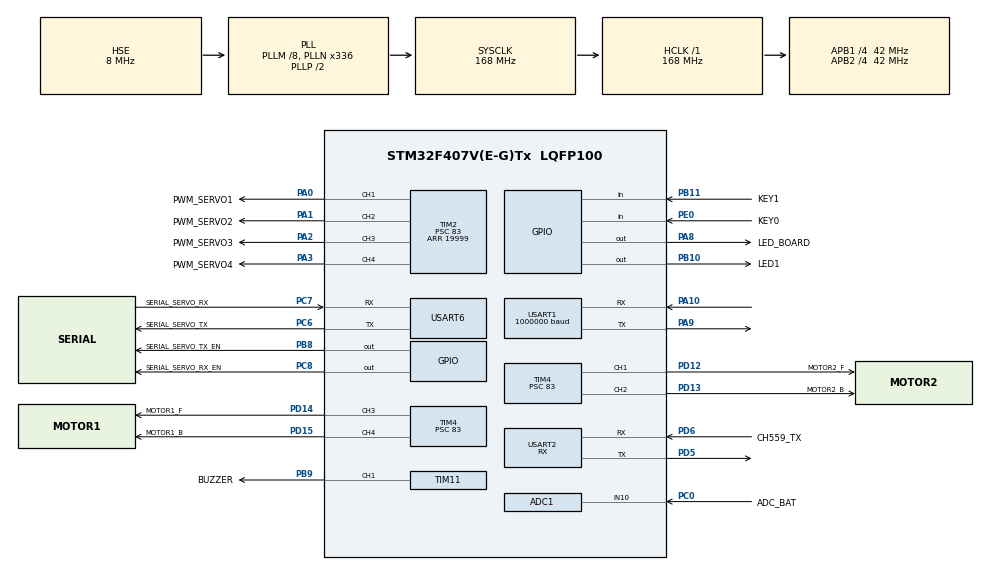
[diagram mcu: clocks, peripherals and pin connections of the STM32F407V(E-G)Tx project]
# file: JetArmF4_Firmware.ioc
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ADC1.Channel-0\#ChannelRegularConversion=ADC_CHANNEL_10
ADC1.NbrOfConversionFlag=1
ADC1.Rank-0\#ChannelRegularConversion=1
ADC1.SamplingTime-0\#ChannelRegularConversion=ADC_SAMPLETIME_3CYCLES
ADC1.master=1
Dma.Request0=USART1_RX
Dma.Request1=USART1_TX
Dma.USART1_RX.0.Direction=DMA_PERIPH_TO_MEMORY
Dma.USART1_RX.0.FIFOMode=DMA_FIFOMODE_DISABLE
Dma.USART1_RX.0.Instance=DMA2_Stream2
Dma.USART1_RX.0.MemDataAlignment=DMA_MDATAALIGN_BYTE
Dma.USART1_RX.0.MemInc=DMA_MINC_ENABLE
Dma.USART1_RX.0.Mode=DMA_NORMAL
Dma.USART1_RX.0.PeriphDataAlignment=DMA_PDATAALIGN_BYTE
Dma.USART1_RX.0.PeriphInc=DMA_PINC_DISABLE
Dma.USART1_RX.0.Priority=DMA_PRIORITY_HIGH
Dma.USART1_TX.1.Direction=DMA_MEMORY_TO_PERIPH
Dma.USART1_TX.1.FIFOMode=DMA_FIFOMODE_DISABLE
Dma.USART1_TX.1.Instance=DMA2_Stream7
Dma.USART1_TX.1.MemDataAlignment=DMA_MDATAALIGN_BYTE
Dma.USART1_TX.1.MemInc=DMA_MINC_ENABLE
Dma.USART1_TX.1.Mode=DMA_NORMAL
Dma.USART1_TX.1.PeriphDataAlignment=DMA_PDATAALIGN_BYTE
Dma.USART1_TX.1.PeriphInc=DMA_PINC_DISABLE
Dma.USART1_TX.1.Priority=DMA_PRIORITY_HIGH
FREERTOS.BinarySemaphores01=serial_servo_rx_complete,Dynamic,NULL;packet_tx_idle,Dynamic,NULL;packet_rx_not_empty,Dynamic,NULL
FREERTOS.Queues01=led0_ctrl_queue,5,16,1,Dynamic,NULL,NULL;led1_ctrl_queue,5,16,1,Dynamic,NULL,NULL;packet_tx_queue,32,void*,0,Dynamic,NULL,NULL
FREERTOS.Tasks01=defaultTask,24,256,StartDefaultTask,Default,NULL,Dynamic,NULL,NULL;app_main_task,25,512,app_main,As weak,NULL,Dynamic,NULL,NULL;packet_rx_task,37,2048,packet_rx_task_entry,As weak,NULL,Dynamic,NULL,NULL;packet_tx_task,35,1024,packet_tx_task_entry,As weak,NULL,Dynamic,NULL,NULL
FREERTOS.Timers01=buzzer_timer,buzzer_timer_callback,osTimerPeriodic,As weak,NULL,Dynamic,NULL;led_timer,led_timer_callback,osTimerPeriodic,As weak,NULL,Dynamic,NULL;button_timer,button_timer_callback,osTimerPeriodic,As weak,NULL,Dynamic,NULL
FREERTOS.configENABLE_FPU=1
FREERTOS.configMINIMAL_STACK_SIZE=256
FREERTOS.configTOTAL_HEAP_SIZE=25360
FREERTOS.configUSE_MALLOC_FAILED_HOOK=1
Mcu.Family=STM32F4
Mcu.Name=STM32F407V(E-G)Tx
Mcu.Package=LQFP100
NVIC.DMA2_Stream2_IRQn=true\:5\:0\:true\:true\:true\:3\:true\:false\:true\:true
NVIC.DMA2_Stream7_IRQn=true\:5\:0\:true\:true\:true\:4\:true\:false\:true\:true
NVIC.PriorityGroup=NVIC_PRIORITYGROUP_4
NVIC.TIM2_IRQn=true\:6\:0\:true\:true\:true\:1\:true\:true\:false\:true
NVIC.TIM8_TRG_COM_TIM14_IRQn=true\:15\:0\:true\:false\:true\:false\:false\:true\:true
NVIC.TimeBase=TIM8_TRG_COM_TIM14_IRQn
NVIC.TimeBaseIP=TIM14
NVIC.USART1_IRQn=true\:7\:0\:true\:true\:true\:2\:true\:true\:true\:true
NVIC.USART6_IRQn=true\:5\:0\:true\:true\:true\:5\:true\:true\:false\:true
PA0-WKUP.GPIO_Label=PWM_SERVO1
PA0-WKUP.Signal=S_TIM2_CH1_ETR
PA1.GPIO_Label=PWM_SERVO2
PA1.Signal=S_TIM2_CH2
PA10.Mode=Asynchronous
PA10.Signal=USART1_RX
PA13.Mode=Serial_Wire
PA13.Signal=SYS_JTMS-SWDIO
PA14.Mode=Serial_Wire
PA14.Signal=SYS_JTCK-SWCLK
PA2.GPIO_Label=PWM_SERVO3
PA2.Signal=S_TIM2_CH3
PA3.GPIO_Label=PWM_SERVO4
PA3.Signal=S_TIM2_CH4
PA8.GPIO_Label=LED_BOARD
PA8.PinState=GPIO_PIN_RESET
PA8.Signal=GPIO_Output
PA9.Mode=Asynchronous
PA9.Signal=USART1_TX
PB10.GPIO_Label=LED1
PB10.PinState=GPIO_PIN_RESET
PB10.Signal=GPIO_Output
PB11.GPIO_Label=KEY1
PB11.GPIO_PuPd=GPIO_PULLUP
PB11.Signal=GPIO_Input
PB8.GPIO_Label=SERIAL_SERVO_TX_EN
PB8.GPIO_Speed=GPIO_SPEED_FREQ_VERY_HIGH
PB8.PinState=GPIO_PIN_SET
PB8.Signal=GPIO_Output
PB9.GPIO_Label=BUZZER
PB9.Signal=S_TIM11_CH1
PC0.GPIO_Label=ADC_BAT
PC0.Signal=ADCx_IN10
PC6.GPIO_Label=SERIAL_SERVO_TX
PC6.Mode=Asynchronous
PC6.Signal=USART6_TX
PC7.GPIO_Label=SERIAL_SERVO_RX
PC7.Mode=Asynchronous
PC7.Signal=USART6_RX
PC8.GPIO_Label=SERIAL_SERVO_RX_EN
PC8.GPIO_Speed=GPIO_SPEED_FREQ_VERY_HIGH
PC8.PinState=GPIO_PIN_SET
PC8.Signal=GPIO_Output
PD12.GPIO_Label=MOTOR2_F
PD12.GPIO_Speed=GPIO_SPEED_FREQ_VERY_HIGH
PD12.Signal=S_TIM4_CH1
PD13.GPIO_Label=MOTOR2_B
PD13.GPIO_Speed=GPIO_SPEED_FREQ_VERY_HIGH
PD13.Signal=S_TIM4_CH2
PD14.GPIO_Label=MOTOR1_F
PD14.GPIO_Speed=GPIO_SPEED_FREQ_VERY_HIGH
PD14.Signal=S_TIM4_CH3
PD15.GPIO_Label=MOTOR1_B
PD15.GPIO_Speed=GPIO_SPEED_FREQ_VERY_HIGH
PD15.Signal=S_TIM4_CH4
PD5.Mode=Asynchronous
PD5.Signal=USART2_TX
PD6.GPIO_Label=CH559_TX
PD6.Mode=Asynchronous
PD6.Signal=USART2_RX
PE0.GPIO_Label=KEY0
PE0.Signal=GPIO_Input
PH0-OSC_IN.Mode=HSE-External-Oscillator
PH0-OSC_IN.Signal=RCC_OSC_IN
PH1-OSC_OUT.Mode=HSE-External-Oscillator
PH1-OSC_OUT.Signal=RCC_OSC_OUT
ProjectManager.HeapSize=0x200
ProjectManager.StackSize=0x400
ProjectManager.TargetToolchain=Makefile
RCC.48MHZClocksFreq_Value=84000000
RCC.AHBFreq_Value=168000000
RCC.APB1CLKDivider=RCC_HCLK_DIV4
RCC.APB1Freq_Value=42000000
RCC.APB1TimFreq_Value=84000000
RCC.APB2CLKDivider=RCC_HCLK_DIV4
RCC.APB2Freq_Value=42000000
RCC.APB2TimFreq_Value=84000000
RCC.CortexFreq_Value=168000000
RCC.EnbaleCSS=true
RCC.HCLKFreq_Value=168000000
RCC.HSE_VALUE=8000000
RCC.HSI_VALUE=16000000
RCC.LSE_VALUE=32768
RCC.PLLM=8
RCC.PLLN=336
RCC.PLLSourceVirtual=RCC_PLLSOURCE_HSE
RCC.SYSCLKFreq_VALUE=168000000
RCC.SYSCLKSource=RCC_SYSCLKSOURCE_PLLCLK
RCC.VCOOutputFreq_Value=336000000
SH.ADCx_IN10.0=ADC1_IN10,IN10
SH.S_TIM11_CH1.0=TIM11_CH1,PWM Generation1 CH1
SH.S_TIM2_CH1_ETR.0=TIM2_CH1,PWM Generation1 CH1
SH.S_TIM2_CH2.0=TIM2_CH2,PWM Generation2 CH2
SH.S_TIM2_CH3.0=TIM2_CH3,PWM Generation3 CH3
SH.S_TIM2_CH4.0=TIM2_CH4,PWM Generation4 CH4
SH.S_TIM4_CH1.0=TIM4_CH1,PWM Generation1 CH1
SH.S_TIM4_CH2.0=TIM4_CH2,PWM Generation2 CH2
SH.S_TIM4_CH3.0=TIM4_CH3,PWM Generation3 CH3
SH.S_TIM4_CH4.0=TIM4_CH4,PWM Generation4 CH4
TIM11.AutoReloadPreload=TIM_AUTORELOAD_PRELOAD_ENABLE
TIM11.Channel=TIM_CHANNEL_1
TIM11.OCFastMode_PWM=TIM_OCFAST_ENABLE
TIM11.Period=99
TIM11.Prescaler=839
TIM11.Pulse=0
TIM2.AutoReloadPreload=TIM_AUTORELOAD_PRELOAD_ENABLE
TIM2.Channel-PWM\ Generation1\ CH1=TIM_CHANNEL_1
TIM2.Channel-PWM\ Generation2\ CH2=TIM_CHANNEL_2
TIM2.Channel-PWM\ Generation3\ CH3=TIM_CHANNEL_3
TIM2.Channel-PWM\ Generation4\ CH4=TIM_CHANNEL_4
TIM2.OC4Preload_PWM=ENABLE
TIM2.OCFastMode_PWM-PWM\ Generation1\ CH1=TIM_OCFAST_ENABLE
TIM2.OCFastMode_PWM-PWM\ Generation2\ CH2=TIM_OCFAST_ENABLE
TIM2.OCFastMode_PWM-PWM\ Generation3\ CH3=TIM_OCFAST_ENABLE
TIM2.OCFastMode_PWM-PWM\ Generation4\ CH4=TIM_OCFAST_ENABLE
TIM2.Period=19999
TIM2.Prescaler=83
TIM4.Channel-PWM\ Generation1\ CH1=TIM_CHANNEL_1
TIM4.Channel-PWM\ Generation2\ CH2=TIM_CHANNEL_2
TIM4.Channel-PWM\ Generation3\ CH3=TIM_CHANNEL_3
TIM4.Channel-PWM\ Generation4\ CH4=TIM_CHANNEL_4
TIM4.OC1Preload_PWM=DISABLE
TIM4.OC2Preload_PWM=DISABLE
TIM4.OC3Preload_PWM=DISABLE
TIM4.OC4Preload_PWM=DISABLE
TIM4.OCFastMode_PWM-PWM\ Generation1\ CH1=TIM_OCFAST_ENABLE
TIM4.OCFastMode_PWM-PWM\ Generation2\ CH2=TIM_OCFAST_ENABLE
TIM4.OCFastMode_PWM-PWM\ Generation3\ CH3=TIM_OCFAST_ENABLE
TIM4.OCFastMode_PWM-PWM\ Generation4\ CH4=TIM_OCFAST_ENABLE
TIM4.Period=9999
TIM4.Prescaler=83
TIM4.Pulse-PWM\ Generation1\ CH1=0
TIM4.Pulse-PWM\ Generation2\ CH2=0
TIM4.Pulse-PWM\ Generation3\ CH3=0
TIM4.Pulse-PWM\ Generation4\ CH4=0
USART1.BaudRate=1000000
USART1.VirtualMode=VM_ASYNC
USART2.Mode=MODE_RX
USART2.VirtualMode=VM_ASYNC
USART6.VirtualMode=VM_ASYNC
VP_ADC1_Vref_Input.Mode=IN-Vrefint
VP_FREERTOS_VS_CMSIS_V2.Mode=CMSIS_V2
VP_SYS_VS_tim14.Mode=TIM14
VP_TIM11_VS_ClockSourceINT.Mode=Enable_Timer
VP_TIM2_VS_ClockSourceINT.Mode=Internal
board=custom

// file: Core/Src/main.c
/* USER CODE BEGIN Header */
/**
  ******************************************************************************
  * @file           : main.c
  * @brief          : Main program body
  ******************************************************************************
  * @attention
  *
  * Copyright (c) 2023 STMicroelectronics.
  * All rights reserved.
  *
  * This software is licensed under terms that can be found in the LICENSE file
  * in the root directory of this software component.
  * If no LICENSE file comes with this software, it is provided AS-IS.
  *
  ******************************************************************************
  */
/* USER CODE END Header */
#include "main.h"
#include "cmsis_os.h"
#include "adc.h"
#include "dma.h"
#include "tim.h"
#include "usart.h"
#include "gpio.h"

/* USER CODE BEGIN Includes */
#include "global_include.h"
#include "EventRecorder.h"
/* USER CODE END Includes */

void SystemClock_Config(void);
void MX_FREERTOS_Init(void);
static void MX_NVIC_Init(void);

int main(void)
{
  /* USER CODE BEGIN 1 */
	lwmem_assignmem(lwmem_regions);  /* Dynamic memory initialization*/
	EventRecorderInitialize(EventRecordAll, 1U);
	EventRecorderStart();

  /* USER CODE END 1 */

  /* MCU Configuration--------------------------------------------------------*/

  /* Reset of all peripherals, Initializes the Flash interface and the Systick. */
  HAL_Init();

  /* Configure the system clock */
  SystemClock_Config();

  /* Initialize all configured peripherals */
  MX_GPIO_Init();
  MX_DMA_Init();
  MX_ADC1_Init();
  MX_TIM2_Init();
  MX_TIM4_Init();
  MX_TIM11_Init();
  MX_USART1_UART_Init();
  MX_USART2_UART_Init();
  MX_USART6_UART_Init();

  /* Initialize interrupts */
  MX_NVIC_Init();
  /* USER CODE BEGIN 2 */
 packet_init();

  /* USER CODE END 2 */

  /* Init scheduler */
  osKernelInitialize();  /* Call init function for freertos objects (in freertos.c) */
  MX_FREERTOS_Init();

  /* Start scheduler */
  osKernelStart();
  /* We should never get here as control is now taken by the scheduler */
  /* Infinite loop */
  while (1)
  {

  }
}

void SystemClock_Config(void)
{
  RCC_OscInitTypeDef RCC_OscInitStruct = {0};
  RCC_ClkInitTypeDef RCC_ClkInitStruct = {0};

  /** Configure the main internal regulator output voltage
  */
  __HAL_RCC_PWR_CLK_ENABLE();
  __HAL_PWR_VOLTAGESCALING_CONFIG(PWR_REGULATOR_VOLTAGE_SCALE1);

  /** Initializes the RCC Oscillators according to the specified parameters
  * in the RCC_OscInitTypeDef structure.
  */
  RCC_OscInitStruct.OscillatorType = RCC_OSCILLATORTYPE_HSE;
  RCC_OscInitStruct.HSEState = RCC_HSE_ON;
  RCC_OscInitStruct.PLL.PLLState = RCC_PLL_ON;
  RCC_OscInitStruct.PLL.PLLSource = RCC_PLLSOURCE_HSE;
  RCC_OscInitStruct.PLL.PLLM = 8;
  RCC_OscInitStruct.PLL.PLLN = 336;
  RCC_OscInitStruct.PLL.PLLP = RCC_PLLP_DIV2;
  RCC_OscInitStruct.PLL.PLLQ = 4;
  if (HAL_RCC_OscConfig(&RCC_OscInitStruct) != HAL_OK)
  {
    Error_Handler();
  }

  /** Initializes the CPU, AHB and APB buses clocks
  */
  RCC_ClkInitStruct.ClockType = RCC_CLOCKTYPE_HCLK|RCC_CLOCKTYPE_SYSCLK
                              |RCC_CLOCKTYPE_PCLK1|RCC_CLOCKTYPE_PCLK2;
  RCC_ClkInitStruct.SYSCLKSource = RCC_SYSCLKSOURCE_PLLCLK;
  RCC_ClkInitStruct.AHBCLKDivider = RCC_SYSCLK_DIV1;
  RCC_ClkInitStruct.APB1CLKDivider = RCC_HCLK_DIV4;
  RCC_ClkInitStruct.APB2CLKDivider = RCC_HCLK_DIV4;

  if (HAL_RCC_ClockConfig(&RCC_ClkInitStruct, FLASH_LATENCY_5) != HAL_OK)
  {
    Error_Handler();
  }

  /** Enables the Clock Security System
  */
  HAL_RCC_EnableCSS();
}

/**
  * @brief NVIC Configuration.
  * @retval None
  */
static void MX_NVIC_Init(void)
{
  /* TIM2_IRQn interrupt configuration */
  HAL_NVIC_SetPriority(TIM2_IRQn, 6, 0);
  HAL_NVIC_EnableIRQ(TIM2_IRQn);
  /* USART1_IRQn interrupt configuration */
  HAL_NVIC_SetPriority(USART1_IRQn, 7, 0);
  HAL_NVIC_EnableIRQ(USART1_IRQn);
  /* DMA2_Stream2_IRQn interrupt configuration */
  HAL_NVIC_SetPriority(DMA2_Stream2_IRQn, 5, 0);
  HAL_NVIC_EnableIRQ(DMA2_Stream2_IRQn);
  /* DMA2_Stream7_IRQn interrupt configuration */
  HAL_NVIC_SetPriority(DMA2_Stream7_IRQn, 5, 0);
  HAL_NVIC_EnableIRQ(DMA2_Stream7_IRQn);
  /* USART6_IRQn interrupt configuration */
  HAL_NVIC_SetPriority(USART6_IRQn, 5, 0);
  HAL_NVIC_EnableIRQ(USART6_IRQn);
}

void HAL_TIM_PeriodElapsedCallback(TIM_HandleTypeDef *htim)
{
  if (htim->Instance == TIM14) {
    HAL_IncTick();
  }
}

void Error_Handler(void)
{
  __disable_irq();
  while (1)
  {
  }
}

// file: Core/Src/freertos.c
/* USER CODE BEGIN Header */
/**
  ******************************************************************************
  * File Name          : freertos.c
  * Description        : Code for freertos applications
  ******************************************************************************
  * @attention
  *
  * Copyright (c) 2023 STMicroelectronics.
  * All rights reserved.
  *
  * This software is licensed under terms that can be found in the LICENSE file
  * in the root directory of this software component.
  * If no LICENSE file comes with this software, it is provided AS-IS.
  *
  ******************************************************************************
  */
/* USER CODE END Header */

#include "FreeRTOS.h"
#include "task.h"
#include "main.h"
#include "cmsis_os.h"

/* Definitions for defaultTask */
osThreadId_t defaultTaskHandle;
const osThreadAttr_t defaultTask_attributes = {
  .name = "defaultTask",
  .stack_size = 256 * 4,
  .priority = (osPriority_t) osPriorityNormal,
};
/* Definitions for app_main_task */
osThreadId_t app_main_taskHandle;
const osThreadAttr_t app_main_task_attributes = {
  .name = "app_main_task",
  .stack_size = 512 * 4,
  .priority = (osPriority_t) osPriorityNormal1,
};
/* Definitions for packet_rx_task */
osThreadId_t packet_rx_taskHandle;
const osThreadAttr_t packet_rx_task_attributes = {
  .name = "packet_rx_task",
  .stack_size = 2048 * 4,
  .priority = (osPriority_t) osPriorityAboveNormal5,
};
/* Definitions for packet_tx_task */
osThreadId_t packet_tx_taskHandle;
const osThreadAttr_t packet_tx_task_attributes = {
  .name = "packet_tx_task",
  .stack_size = 1024 * 4,
  .priority = (osPriority_t) osPriorityAboveNormal3,
};
/* Definitions for led0_ctrl_queue */
osMessageQueueId_t led0_ctrl_queueHandle;
const osMessageQueueAttr_t led0_ctrl_queue_attributes = {
  .name = "led0_ctrl_queue"
};
/* Definitions for led1_ctrl_queue */
osMessageQueueId_t led1_ctrl_queueHandle;
const osMessageQueueAttr_t led1_ctrl_queue_attributes = {
  .name = "led1_ctrl_queue"
};
/* Definitions for packet_tx_queue */
osMessageQueueId_t packet_tx_queueHandle;
const osMessageQueueAttr_t packet_tx_queue_attributes = {
  .name = "packet_tx_queue"
};
/* Definitions for buzzer_timer */
osTimerId_t buzzer_timerHandle;
const osTimerAttr_t buzzer_timer_attributes = {
  .name = "buzzer_timer"
};
/* Definitions for led_timer */
osTimerId_t led_timerHandle;
const osTimerAttr_t led_timer_attributes = {
  .name = "led_timer"
};
/* Definitions for button_timer */
osTimerId_t button_timerHandle;
const osTimerAttr_t button_timer_attributes = {
  .name = "button_timer"
};
/* Definitions for serial_servo_rx_complete */
osSemaphoreId_t serial_servo_rx_completeHandle;
const osSemaphoreAttr_t serial_servo_rx_complete_attributes = {
  .name = "serial_servo_rx_complete"
};
/* Definitions for packet_tx_idle */
osSemaphoreId_t packet_tx_idleHandle;
const osSemaphoreAttr_t packet_tx_idle_attributes = {
  .name = "packet_tx_idle"
};
/* Definitions for packet_rx_not_empty */
osSemaphoreId_t packet_rx_not_emptyHandle;
const osSemaphoreAttr_t packet_rx_not_empty_attributes = {
  .name = "packet_rx_not_empty"
};

void StartDefaultTask(void *argument);
void app_main(void *argument);
void packet_rx_task_entry(void *argument);
void packet_tx_task_entry(void *argument);
void buzzer_timer_callback(void *argument);
void led_timer_callback(void *argument);
void button_timer_callback(void *argument);

void MX_FREERTOS_Init(void); /* (MISRA C 2004 rule 8.1) */

/* Hook prototypes */
void vApplicationMallocFailedHook(void);

/* USER CODE BEGIN 5 */
void vApplicationMallocFailedHook(void)
{
   /* vApplicationMallocFailedHook() will only be called if
   configUSE_MALLOC_FAILED_HOOK is set to 1 in FreeRTOSConfig.h. It is a hook
   function that will get called if a call to pvPortMalloc() fails.
   pvPortMalloc() is called internally by the kernel whenever a task, queue,
   timer or semaphore is created. It is also called by various parts of the
   demo application. If heap_1.c or heap_2.c are used, then the size of the
   heap available to pvPortMalloc() is defined by configTOTAL_HEAP_SIZE in
   FreeRTOSConfig.h, and the xPortGetFreeHeapSize() API function can be used
   to query the size of free heap space that remains (although it does not
   provide information on how the remaining heap might be fragmented). */
}
/* USER CODE END 5 */

void MX_FREERTOS_Init(void) {

  /* Create the semaphores(s) */
  /* creation of serial_servo_rx_complete */
  serial_servo_rx_completeHandle = osSemaphoreNew(1, 1, &serial_servo_rx_complete_attributes);

  /* creation of packet_tx_idle */
  packet_tx_idleHandle = osSemaphoreNew(1, 1, &packet_tx_idle_attributes);

  /* creation of packet_rx_not_empty */
  packet_rx_not_emptyHandle = osSemaphoreNew(1, 1, &packet_rx_not_empty_attributes);

  /* Create the timer(s) */
  /* creation of buzzer_timer */
  buzzer_timerHandle = osTimerNew(buzzer_timer_callback, osTimerPeriodic, NULL, &buzzer_timer_attributes);

  /* creation of led_timer */
  led_timerHandle = osTimerNew(led_timer_callback, osTimerPeriodic, NULL, &led_timer_attributes);

  /* creation of button_timer */
  button_timerHandle = osTimerNew(button_timer_callback, osTimerPeriodic, NULL, &button_timer_attributes);

  /* Create the queue(s) */
  /* creation of led0_ctrl_queue */
  led0_ctrl_queueHandle = osMessageQueueNew (5, 16, &led0_ctrl_queue_attributes);

  /* creation of led1_ctrl_queue */
  led1_ctrl_queueHandle = osMessageQueueNew (5, 16, &led1_ctrl_queue_attributes);

  /* creation of packet_tx_queue */
  packet_tx_queueHandle = osMessageQueueNew (32, sizeof(void*), &packet_tx_queue_attributes);

  /* Create the thread(s) */
  /* creation of defaultTask */
  defaultTaskHandle = osThreadNew(StartDefaultTask, NULL, &defaultTask_attributes);

  /* creation of app_main_task */
  app_main_taskHandle = osThreadNew(app_main, NULL, &app_main_task_attributes);

  /* creation of packet_rx_task */
  packet_rx_taskHandle = osThreadNew(packet_rx_task_entry, NULL, &packet_rx_task_attributes);

  /* creation of packet_tx_task */
  packet_tx_taskHandle = osThreadNew(packet_tx_task_entry, NULL, &packet_tx_task_attributes);

}

void StartDefaultTask(void *argument)
{
  for(;;)
  {
    osDelay(1);
  }
}

__weak void app_main(void *argument)
{
  for(;;)
  {
    osDelay(1);
  }
}

__weak void packet_rx_task_entry(void *argument)
{
  for(;;)
  {
    osDelay(1);
  }
}

__weak void packet_tx_task_entry(void *argument)
{
  for(;;)
  {
    osDelay(1);
  }
}

/* buzzer_timer_callback function */
__weak void buzzer_timer_callback(void *argument)
{
}

/* led_timer_callback function */
__weak void led_timer_callback(void *argument)
{
}

/* button_timer_callback function */
__weak void button_timer_callback(void *argument)
{
}
